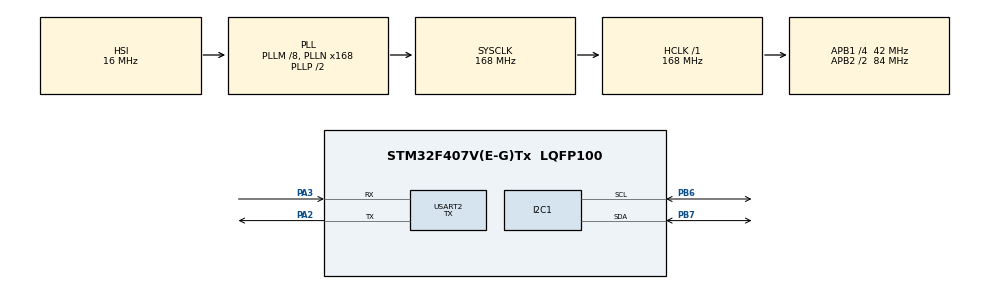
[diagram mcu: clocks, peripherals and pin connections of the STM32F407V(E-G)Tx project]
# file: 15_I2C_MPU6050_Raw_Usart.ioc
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I2C1.DutyCycle=I2C_DUTYCYCLE_16_9
I2C1.I2C_Mode=I2C_Fast
Mcu.Family=STM32F4
Mcu.Name=STM32F407V(E-G)Tx
Mcu.Package=LQFP100
NVIC.PriorityGroup=NVIC_PRIORITYGROUP_4
PA13.Mode=Serial_Wire
PA13.Signal=SYS_JTMS-SWDIO
PA14.Mode=Serial_Wire
PA14.Signal=SYS_JTCK-SWCLK
PA2.Mode=Asynchronous
PA2.Signal=USART2_TX
PA3.Mode=Asynchronous
PA3.Signal=USART2_RX
PB6.Mode=I2C
PB6.Signal=I2C1_SCL
PB7.Mode=I2C
PB7.Signal=I2C1_SDA
ProjectManager.HeapSize=0x200
ProjectManager.StackSize=0x400
ProjectManager.TargetToolchain=MDK-ARM V5
RCC.48MHZClocksFreq_Value=84000000
RCC.AHBFreq_Value=168000000
RCC.APB1CLKDivider=RCC_HCLK_DIV4
RCC.APB1Freq_Value=42000000
RCC.APB1TimFreq_Value=84000000
RCC.APB2CLKDivider=RCC_HCLK_DIV2
RCC.APB2Freq_Value=84000000
RCC.APB2TimFreq_Value=168000000
RCC.CortexFreq_Value=168000000
RCC.HCLKFreq_Value=168000000
RCC.HSE_VALUE=25000000
RCC.HSI_VALUE=16000000
RCC.LSE_VALUE=32768
RCC.PLLM=8
RCC.PLLN=168
RCC.SYSCLKFreq_VALUE=168000000
RCC.SYSCLKSource=RCC_SYSCLKSOURCE_PLLCLK
RCC.VCOOutputFreq_Value=336000000
USART2.Mode=MODE_TX
USART2.VirtualMode=VM_ASYNC
board=15_I2C_MPU6050_Raw_Usart

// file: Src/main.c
/**
  ******************************************************************************
  * File Name          : main.c
  * Description        : Main program body
  ******************************************************************************
  ** This notice applies to any and all portions of this file
  * that are not between comment pairs USER CODE BEGIN and
  * USER CODE END. Other portions of this file, whether
  * inserted by the user or by software development tools
  * are owned by their respective copyright owners.
  *
  * COPYRIGHT(c) 2018 STMicroelectronics
  *
  * Redistribution and use in source and binary forms, with or without modification,
  * are permitted provided that the following conditions are met:
  *   1. Redistributions of source code must retain the above copyright notice,
  *      this list of conditions and the following disclaimer.
  *   2. Redistributions in binary form must reproduce the above copyright notice,
  *      this list of conditions and the following disclaimer in the documentation
  *      and/or other materials provided with the distribution.
  *   3. Neither the name of STMicroelectronics nor the names of its contributors
  *      may be used to endorse or promote products derived from this software
  *      without specific prior written permission.
  *
  * THIS SOFTWARE IS PROVIDED BY THE COPYRIGHT HOLDERS AND CONTRIBUTORS "AS IS"
  * AND ANY EXPRESS OR IMPLIED WARRANTIES, INCLUDING, BUT NOT LIMITED TO, THE
  * IMPLIED WARRANTIES OF MERCHANTABILITY AND FITNESS FOR A PARTICULAR PURPOSE ARE
  * DISCLAIMED. IN NO EVENT SHALL THE COPYRIGHT HOLDER OR CONTRIBUTORS BE LIABLE
  * FOR ANY DIRECT, INDIRECT, INCIDENTAL, SPECIAL, EXEMPLARY, OR CONSEQUENTIAL
  * DAMAGES (INCLUDING, BUT NOT LIMITED TO, PROCUREMENT OF SUBSTITUTE GOODS OR
  * SERVICES; LOSS OF USE, DATA, OR PROFITS; OR BUSINESS INTERRUPTION) HOWEVER
  * CAUSED AND ON ANY THEORY OF LIABILITY, WHETHER IN CONTRACT, STRICT LIABILITY,
  * OR TORT (INCLUDING NEGLIGENCE OR OTHERWISE) ARISING IN ANY WAY OUT OF THE USE
  * OF THIS SOFTWARE, EVEN IF ADVISED OF THE POSSIBILITY OF SUCH DAMAGE.
  *
  ******************************************************************************
  */
#include "main.h"
#include "stm32f4xx_hal.h"
// tm libdeb eklenenler:
#include "defines.h"
#include "tm_stm32_mpu6050.h"
// defineye bazi eklemeler yapildi mpu6050 için

//#include <stdio.h>
//#include <math.h>

int16_t ax=0,ay=0,az=0,gx=0,gy=0,gz=0;
float temperature=0;
char   data[120];

TM_MPU6050_t MPU6050_Sensor;   // degisken tanimladik...

I2C_HandleTypeDef hi2c1;

UART_HandleTypeDef huart2;

/* USER CODE BEGIN PV */
/* Private variables ---------------------------------------------------------*/

/* USER CODE END PV */

void SystemClock_Config(void);
static void MX_GPIO_Init(void);
static void MX_I2C1_Init(void);
static void MX_USART2_UART_Init(void);

/* USER CODE BEGIN PFP */
/* Private function prototypes -----------------------------------------------*/

/* USER CODE END PFP */

int main(void)
{

  /* MCU Configuration----------------------------------------------------------*/

  /* Reset of all peripherals, Initializes the Flash interface and the Systick. */
  HAL_Init();

  /* Configure the system clock */
  SystemClock_Config();

  /* Initialize all configured peripherals */
  MX_GPIO_Init();
  MX_I2C1_Init();
  MX_USART2_UART_Init();

  /* USER CODE BEGIN 2 */

// Initialize MPU6050 sensor 0,address=0xD0, AD0 pin on sensor is low...
// suan bir tane mpu6050 bagli ve adresi 0 bir tane daha baglayip adresini 1 yapabiliriz.
 while(TM_MPU6050_Init(&MPU6050_Sensor, TM_MPU6050_Device_0, TM_MPU6050_Accelerometer_8G, TM_MPU6050_Gyroscope_250s) != TM_MPU6050_Result_Ok)
 {

 }

HAL_Delay(5000);

  /* USER CODE END 2 */

  /* Infinite loop */
  while (1)
  {

// read all data of mpu6050  sensor
		HAL_Delay(500);

		TM_MPU6050_ReadAll(&MPU6050_Sensor); // tüm degerler okundu

		ax= MPU6050_Sensor.Accelerometer_X;
		ay= MPU6050_Sensor.Accelerometer_Y;
		az= MPU6050_Sensor.Accelerometer_Z;
		gx=MPU6050_Sensor.Gyroscope_X;
		gy=MPU6050_Sensor.Gyroscope_Y;
		gz=MPU6050_Sensor.Gyroscope_Z;
		temperature= MPU6050_Sensor.Temperature; // degerleri degiskenlere atadik
		// ve usart ile gönderiyoruz......

		HAL_UART_Transmit(&huart2,(uint8_t*)data,sprintf(data,
		"Accelerometer  value\n- X:%d\n- Y:%d\n- Z:%d\nGyro values\n- X:%d\n- Y:%d\n- Z:%d\nTemperature\n- %3.4f\n\n\n"
		,ax,ay,az,gx,gy,gz,temperature),1000); // Polling metodu

  }

}

/** System Clock Configuration
*/
void SystemClock_Config(void)
{

  RCC_OscInitTypeDef RCC_OscInitStruct;
  RCC_ClkInitTypeDef RCC_ClkInitStruct;

    /**Configure the main internal regulator output voltage
    */
  __HAL_RCC_PWR_CLK_ENABLE();

  __HAL_PWR_VOLTAGESCALING_CONFIG(PWR_REGULATOR_VOLTAGE_SCALE1);

    /**Initializes the CPU, AHB and APB busses clocks
    */
  RCC_OscInitStruct.OscillatorType = RCC_OSCILLATORTYPE_HSI;
  RCC_OscInitStruct.HSIState = RCC_HSI_ON;
  RCC_OscInitStruct.HSICalibrationValue = 16;
  RCC_OscInitStruct.PLL.PLLState = RCC_PLL_ON;
  RCC_OscInitStruct.PLL.PLLSource = RCC_PLLSOURCE_HSI;
  RCC_OscInitStruct.PLL.PLLM = 8;
  RCC_OscInitStruct.PLL.PLLN = 168;
  RCC_OscInitStruct.PLL.PLLP = RCC_PLLP_DIV2;
  RCC_OscInitStruct.PLL.PLLQ = 4;
  if (HAL_RCC_OscConfig(&RCC_OscInitStruct) != HAL_OK)
  {
    _Error_Handler(__FILE__, __LINE__);
  }

    /**Initializes the CPU, AHB and APB busses clocks
    */
  RCC_ClkInitStruct.ClockType = RCC_CLOCKTYPE_HCLK|RCC_CLOCKTYPE_SYSCLK
                              |RCC_CLOCKTYPE_PCLK1|RCC_CLOCKTYPE_PCLK2;
  RCC_ClkInitStruct.SYSCLKSource = RCC_SYSCLKSOURCE_PLLCLK;
  RCC_ClkInitStruct.AHBCLKDivider = RCC_SYSCLK_DIV1;
  RCC_ClkInitStruct.APB1CLKDivider = RCC_HCLK_DIV4;
  RCC_ClkInitStruct.APB2CLKDivider = RCC_HCLK_DIV2;

  if (HAL_RCC_ClockConfig(&RCC_ClkInitStruct, FLASH_LATENCY_5) != HAL_OK)
  {
    _Error_Handler(__FILE__, __LINE__);
  }

    /**Configure the Systick interrupt time
    */
  HAL_SYSTICK_Config(HAL_RCC_GetHCLKFreq()/1000);

    /**Configure the Systick
    */
  HAL_SYSTICK_CLKSourceConfig(SYSTICK_CLKSOURCE_HCLK);

  /* SysTick_IRQn interrupt configuration */
  HAL_NVIC_SetPriority(SysTick_IRQn, 0, 0);
}

/* I2C1 init function */
static void MX_I2C1_Init(void)
{

  hi2c1.Instance = I2C1;
  hi2c1.Init.ClockSpeed = 400000;
  hi2c1.Init.DutyCycle = I2C_DUTYCYCLE_16_9;
  hi2c1.Init.OwnAddress1 = 0;
  hi2c1.Init.AddressingMode = I2C_ADDRESSINGMODE_7BIT;
  hi2c1.Init.DualAddressMode = I2C_DUALADDRESS_DISABLE;
  hi2c1.Init.OwnAddress2 = 0;
  hi2c1.Init.GeneralCallMode = I2C_GENERALCALL_DISABLE;
  hi2c1.Init.NoStretchMode = I2C_NOSTRETCH_DISABLE;
  if (HAL_I2C_Init(&hi2c1) != HAL_OK)
  {
    _Error_Handler(__FILE__, __LINE__);
  }

}

/* USART2 init function */
static void MX_USART2_UART_Init(void)
{

  huart2.Instance = USART2;
  huart2.Init.BaudRate = 9600;
  huart2.Init.WordLength = UART_WORDLENGTH_8B;
  huart2.Init.StopBits = UART_STOPBITS_1;
  huart2.Init.Parity = UART_PARITY_NONE;
  huart2.Init.Mode = UART_MODE_TX;
  huart2.Init.HwFlowCtl = UART_HWCONTROL_NONE;
  huart2.Init.OverSampling = UART_OVERSAMPLING_16;
  if (HAL_UART_Init(&huart2) != HAL_OK)
  {
    _Error_Handler(__FILE__, __LINE__);
  }

}

/** Configure pins as
        * Analog
        * Input
        * Output
        * EVENT_OUT
        * EXTI
*/
static void MX_GPIO_Init(void)
{

  /* GPIO Ports Clock Enable */
  __HAL_RCC_GPIOA_CLK_ENABLE();
  __HAL_RCC_GPIOB_CLK_ENABLE();

}

void _Error_Handler(char * file, int line)
{
  while(1)
  {
  }
}

/************************ (C) COPYRIGHT STMicroelectronics *****END OF FILE****/
